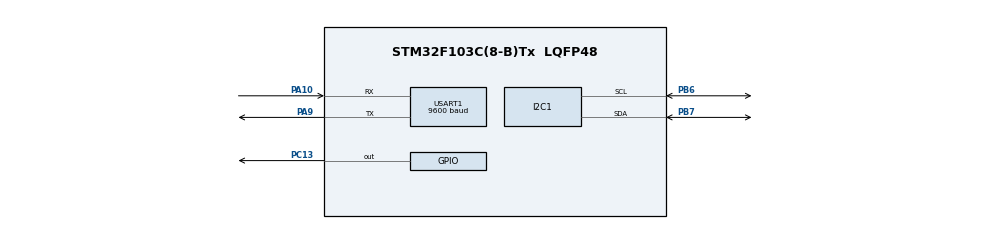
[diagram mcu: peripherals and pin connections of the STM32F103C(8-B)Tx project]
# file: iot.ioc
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Mcu.Family=STM32F1
Mcu.Name=STM32F103C(8-B)Tx
Mcu.Package=LQFP48
NVIC.PriorityGroup=NVIC_PRIORITYGROUP_4
NVIC.USART1_IRQn=true\:0\:0\:false\:false\:true\:true\:true\:true
PA10.Mode=Asynchronous
PA10.Signal=USART1_RX
PA9.Mode=Asynchronous
PA9.Signal=USART1_TX
PB6.Mode=I2C
PB6.Signal=I2C1_SCL
PB7.Mode=I2C
PB7.Signal=I2C1_SDA
PC13-TAMPER-RTC.Signal=GPIO_Output
ProjectManager.HeapSize=0x200
ProjectManager.StackSize=0x400
ProjectManager.TargetToolchain=MDK-ARM V5.32
RCC.APB1Freq_Value=8000000
RCC.APB2Freq_Value=8000000
USART1.BaudRate=9600
USART1.VirtualMode=VM_ASYNC
VP_SYS_VS_ND.Mode=No_Debug
board=custom

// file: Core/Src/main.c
/* USER CODE BEGIN Header */
/**
  ******************************************************************************
  * @file           : main.c
  * @brief          : Main program body
  ******************************************************************************
  * @attention
  *
  * Copyright (c) 2023 STMicroelectronics.
  * All rights reserved.
  *
  * This software is licensed under terms that can be found in the LICENSE file
  * in the root directory of this software component.
  * If no LICENSE file comes with this software, it is provided AS-IS.
  *
  ******************************************************************************
  */
/* USER CODE END Header */
#include "main.h"
#include <string.h>
#define WIDTH 128
#define HEIGHT 64
#define WIRE_MAX 32
#define size_x 8
#define size_y 10
#define TW_START 0x08 // start
#define  TW_REP_START  0x10    // repeat start
#define  TW_MT_SLA_ACK 0x18   // truyen slave addr de ghi co ack
#define  TW_MT_SLA_NACK 0x20 //  truyen slave addr de ghi  ko co ack
#define  TW_MR_SLA_ACK 0x40   // truyen slave addr de doc co ack
#define  TW_MT_DATA_ACK 0x28 // gui dl co ack
#define  TW_MT_DATA_NACK 0x30  // nhan dl khong co ack
#define SSD1306_COLUMNADDR          0x21 ///< See datasheet
#define SSD1306_PAGEADDR            0x22        ///< See datasheet
#define BUFF_SIZE WIDTH*HEIGHT/8

#define addr_oled 0x78
#define MESS_SIZE 32

I2C_HandleTypeDef hi2c1;

UART_HandleTypeDef huart1;

void SystemClock_Config(void);
static void MX_GPIO_Init(void);
static void MX_I2C1_Init(void);
static void MX_USART1_UART_Init(void);

unsigned char buffer[BUFF_SIZE]; //
unsigned char buff[3];
unsigned char buff1[WIRE_MAX];
// rong 128 dai 64
const uint8_t Fonts_10x7 [] = {
0x00, 0x00, 0x00, 0x00, 0x00, 0x00, 0x00, 0x00, 0x00, 0x00,  // sp
0x10, 0x10, 0x10, 0x10, 0x10, 0x10, 0x00, 0x10, 0x00, 0x00,  // !
0x28, 0x28, 0x28, 0x00, 0x00, 0x00, 0x00, 0x00, 0x00, 0x00,  // "
0x24, 0x24, 0x7C, 0x24, 0x48, 0x7C, 0x48, 0x48, 0x00, 0x00,  // #
0x38, 0x54, 0x50, 0x38, 0x14, 0x54, 0x54, 0x38, 0x10, 0x00,  // $
0x20, 0x54, 0x58, 0x30, 0x28, 0x54, 0x14, 0x08, 0x00, 0x00,  // %
0x10, 0x28, 0x28, 0x10, 0x34, 0x48, 0x48, 0x34, 0x00, 0x00,  // &
0x10, 0x10, 0x10, 0x00, 0x00, 0x00, 0x00, 0x00, 0x00, 0x00,  // '
0x08, 0x10, 0x20, 0x20, 0x20, 0x20, 0x20, 0x20, 0x10, 0x08,  // (
0x20, 0x10, 0x08, 0x08, 0x08, 0x08, 0x08, 0x08, 0x10, 0x20,  // )
0x10, 0x38, 0x10, 0x28, 0x00, 0x00, 0x00, 0x00, 0x00, 0x00,  // *
0x00, 0x00, 0x10, 0x10, 0x7C, 0x10, 0x10, 0x00, 0x00, 0x00,  // +
0x00, 0x00, 0x00, 0x00, 0x00, 0x00, 0x00, 0x10, 0x10, 0x10,  // ,
0x00, 0x00, 0x00, 0x00, 0x00, 0x38, 0x00, 0x00, 0x00, 0x00,  // -
0x00, 0x00, 0x00, 0x00, 0x00, 0x00, 0x00, 0x10, 0x00, 0x00,  // .
0x08, 0x08, 0x10, 0x10, 0x10, 0x10, 0x20, 0x20, 0x00, 0x00,  // /
0x38, 0x44, 0x44, 0x54, 0x44, 0x44, 0x44, 0x38, 0x00, 0x00,  // 0
0x10, 0x30, 0x50, 0x10, 0x10, 0x10, 0x10, 0x10, 0x00, 0x00,  // 1
0x38, 0x44, 0x44, 0x04, 0x08, 0x10, 0x20, 0x7C, 0x00, 0x00,  // 2
0x38, 0x44, 0x04, 0x18, 0x04, 0x04, 0x44, 0x38, 0x00, 0x00,  // 3
0x08, 0x18, 0x28, 0x28, 0x48, 0x7C, 0x08, 0x08, 0x00, 0x00,  // 4
0x7C, 0x40, 0x40, 0x78, 0x04, 0x04, 0x44, 0x38, 0x00, 0x00,  // 5
0x38, 0x44, 0x40, 0x78, 0x44, 0x44, 0x44, 0x38, 0x00, 0x00,  // 6
0x7C, 0x04, 0x08, 0x10, 0x10, 0x20, 0x20, 0x20, 0x00, 0x00,  // 7
0x38, 0x44, 0x44, 0x38, 0x44, 0x44, 0x44, 0x38, 0x00, 0x00,  // 8
0x38, 0x44, 0x44, 0x44, 0x3C, 0x04, 0x44, 0x38, 0x00, 0x00,  // 9
0x00, 0x00, 0x10, 0x00, 0x00, 0x00, 0x00, 0x10, 0x00, 0x00,  // :
0x00, 0x00, 0x00, 0x10, 0x00, 0x00, 0x00, 0x10, 0x10, 0x10,  // ;
0x00, 0x00, 0x0C, 0x30, 0x40, 0x30, 0x0C, 0x00, 0x00, 0x00,  // <
0x00, 0x00, 0x00, 0x7C, 0x00, 0x7C, 0x00, 0x00, 0x00, 0x00,  // =
0x00, 0x00, 0x60, 0x18, 0x04, 0x18, 0x60, 0x00, 0x00, 0x00,  // >
0x38, 0x44, 0x04, 0x08, 0x10, 0x10, 0x00, 0x10, 0x00, 0x00,  // ?
0x38, 0x44, 0x4C, 0x54, 0x5C, 0x40, 0x40, 0x38, 0x00, 0x00,  // @
0x10, 0x28, 0x28, 0x28, 0x28, 0x7C, 0x44, 0x44, 0x00, 0x00,  // A
0x78, 0x44, 0x44, 0x78, 0x44, 0x44, 0x44, 0x78, 0x00, 0x00,  // B
0x38, 0x44, 0x40, 0x40, 0x40, 0x40, 0x44, 0x38, 0x00, 0x00,  // C
0x70, 0x48, 0x44, 0x44, 0x44, 0x44, 0x48, 0x70, 0x00, 0x00,  // D
0x7C, 0x40, 0x40, 0x7C, 0x40, 0x40, 0x40, 0x7C, 0x00, 0x00,  // E
0x7C, 0x40, 0x40, 0x78, 0x40, 0x40, 0x40, 0x40, 0x00, 0x00,  // F
0x38, 0x44, 0x40, 0x40, 0x5C, 0x44, 0x44, 0x38, 0x00, 0x00,  // G
0x44, 0x44, 0x44, 0x7C, 0x44, 0x44, 0x44, 0x44, 0x00, 0x00,  // H
0x38, 0x10, 0x10, 0x10, 0x10, 0x10, 0x10, 0x38, 0x00, 0x00,  // I
0x04, 0x04, 0x04, 0x04, 0x04, 0x04, 0x44, 0x38, 0x00, 0x00,  // J
0x44, 0x48, 0x50, 0x60, 0x50, 0x48, 0x48, 0x44, 0x00, 0x00,  // K
0x40, 0x40, 0x40, 0x40, 0x40, 0x40, 0x40, 0x7C, 0x00, 0x00,  // L
0x44, 0x6C, 0x6C, 0x54, 0x44, 0x44, 0x44, 0x44, 0x00, 0x00,  // M
0x44, 0x64, 0x64, 0x54, 0x54, 0x4C, 0x4C, 0x44, 0x00, 0x00,  // N
0x38, 0x44, 0x44, 0x44, 0x44, 0x44, 0x44, 0x38, 0x00, 0x00,  // O
0x78, 0x44, 0x44, 0x44, 0x78, 0x40, 0x40, 0x40, 0x00, 0x00,  // P
0x38, 0x44, 0x44, 0x44, 0x44, 0x44, 0x54, 0x38, 0x04, 0x00,  // Q
0x78, 0x44, 0x44, 0x44, 0x78, 0x48, 0x48, 0x44, 0x00, 0x00,  // R
0x38, 0x44, 0x40, 0x30, 0x08, 0x04, 0x44, 0x38, 0x00, 0x00,  // S
0x7C, 0x10, 0x10, 0x10, 0x10, 0x10, 0x10, 0x10, 0x00, 0x00,  // T
0x44, 0x44, 0x44, 0x44, 0x44, 0x44, 0x44, 0x38, 0x00, 0x00,  // U
0x44, 0x44, 0x44, 0x28, 0x28, 0x28, 0x10, 0x10, 0x00, 0x00,  // V
0x44, 0x44, 0x54, 0x54, 0x54, 0x6C, 0x28, 0x28, 0x00, 0x00,  // W
0x44, 0x28, 0x28, 0x10, 0x10, 0x28, 0x28, 0x44, 0x00, 0x00,  // X
0x44, 0x44, 0x28, 0x28, 0x10, 0x10, 0x10, 0x10, 0x00, 0x00,  // Y
0x7C, 0x04, 0x08, 0x10, 0x10, 0x20, 0x40, 0x7C, 0x00, 0x00,  // Z
0x18, 0x10, 0x10, 0x10, 0x10, 0x10, 0x10, 0x10, 0x10, 0x18,  // [
0x20, 0x20, 0x10, 0x10, 0x10, 0x10, 0x08, 0x08, 0x00, 0x00,  /* \ */
0x30, 0x10, 0x10, 0x10, 0x10, 0x10, 0x10, 0x10, 0x10, 0x30,  // ]
0x10, 0x28, 0x28, 0x44, 0x00, 0x00, 0x00, 0x00, 0x00, 0x00,  // ^
0x00, 0x00, 0x00, 0x00, 0x00, 0x00, 0x00, 0x00, 0x00, 0xFE,  // _
0x20, 0x10, 0x00, 0x00, 0x00, 0x00, 0x00, 0x00, 0x00, 0x00,  // `
0x00, 0x00, 0x38, 0x44, 0x3C, 0x44, 0x4C, 0x34, 0x00, 0x00,  // a
0x40, 0x40, 0x58, 0x64, 0x44, 0x44, 0x64, 0x58, 0x00, 0x00,  // b
0x00, 0x00, 0x38, 0x44, 0x40, 0x40, 0x44, 0x38, 0x00, 0x00,  // c
0x04, 0x04, 0x34, 0x4C, 0x44, 0x44, 0x4C, 0x34, 0x00, 0x00,  // d
0x00, 0x00, 0x38, 0x44, 0x7C, 0x40, 0x44, 0x38, 0x00, 0x00,  // e
0x0C, 0x10, 0x7C, 0x10, 0x10, 0x10, 0x10, 0x10, 0x00, 0x00,  // f
0x00, 0x00, 0x34, 0x4C, 0x44, 0x44, 0x4C, 0x34, 0x04, 0x78,  // g
0x40, 0x40, 0x58, 0x64, 0x44, 0x44, 0x44, 0x44, 0x00, 0x00,  // h
0x10, 0x00, 0x70, 0x10, 0x10, 0x10, 0x10, 0x10, 0x00, 0x00,  // i
0x10, 0x00, 0x70, 0x10, 0x10, 0x10, 0x10, 0x10, 0x10, 0xE0,  // j
0x40, 0x40, 0x48, 0x50, 0x60, 0x50, 0x48, 0x44, 0x00, 0x00,  // k
0x70, 0x10, 0x10, 0x10, 0x10, 0x10, 0x10, 0x10, 0x00, 0x00,  // l
0x00, 0x00, 0x78, 0x54, 0x54, 0x54, 0x54, 0x54, 0x00, 0x00,  // m
0x00, 0x00, 0x58, 0x64, 0x44, 0x44, 0x44, 0x44, 0x00, 0x00,  // n
0x00, 0x00, 0x38, 0x44, 0x44, 0x44, 0x44, 0x38, 0x00, 0x00,  // o
0x00, 0x00, 0x58, 0x64, 0x44, 0x44, 0x64, 0x58, 0x40, 0x40,  // p
0x00, 0x00, 0x34, 0x4C, 0x44, 0x44, 0x4C, 0x34, 0x04, 0x04,  // q
0x00, 0x00, 0x58, 0x64, 0x40, 0x40, 0x40, 0x40, 0x00, 0x00,  // r
0x00, 0x00, 0x38, 0x44, 0x30, 0x08, 0x44, 0x38, 0x00, 0x00,  // s
0x20, 0x20, 0x78, 0x20, 0x20, 0x20, 0x20, 0x18, 0x00, 0x00,  // t
0x00, 0x00, 0x44, 0x44, 0x44, 0x44, 0x4C, 0x34, 0x00, 0x00,  // u
0x00, 0x00, 0x44, 0x44, 0x28, 0x28, 0x28, 0x10, 0x00, 0x00,  // v
0x00, 0x00, 0x54, 0x54, 0x54, 0x6C, 0x28, 0x28, 0x00, 0x00,  // w
0x00, 0x00, 0x44, 0x28, 0x10, 0x10, 0x28, 0x44, 0x00, 0x00,  // x
0x00, 0x00, 0x44, 0x44, 0x28, 0x28, 0x10, 0x10, 0x10, 0x60,  // y
0x00, 0x00, 0x7C, 0x08, 0x10, 0x20, 0x40, 0x7C, 0x00, 0x00,  // z
0x18, 0x10, 0x10, 0x10, 0x20, 0x20, 0x10, 0x10, 0x10, 0x18,  // {
0x10, 0x10, 0x10, 0x10, 0x10, 0x10, 0x10, 0x10, 0x10, 0x10,  // |
0x30, 0x10, 0x10, 0x10, 0x08, 0x08, 0x10, 0x10, 0x10, 0x30,  // }
0x00, 0x00, 0x00, 0x74, 0x4C, 0x00, 0x00, 0x00, 0x00, 0x00,  // ~
};

uint8_t logo_bmp[] =
{ 0x00,0x00,0x00,0x00,0x00,0x00,
  0x00,0x00,0x1f,0xff,0xff,0xf0,
  0x00,0x00,0x3f,0xff,0xff,0xf0,
  0x00,0x00,0x3f,0xff,0xff,0xf0,
  0x00,0x00,0x3f,0xff,0xff,0xf0,
  0x00,0x00,0x3e,0x6f,0xe4,0xf0,
  0x00,0x00,0x3e,0xa7,0x20,0xf0,
  0x00,0x40,0x3e,0x0b,0x21,0xf0,
  0x01,0xf0,0x3e,0x83,0x20,0xf0,
  0x00,0xe0,0x3e,0x53,0x64,0xf0,
  0x00,0xe0,0x3f,0xff,0xff,0xf0,
  0x00,0x00,0x3f,0xff,0xff,0xf0,
  0x00,0x00,0x3f,0xff,0xff,0xf0,
  0x00,0x00,0x3f,0xff,0xef,0xf0,
  0x00,0x00,0x3f,0xfc,0xff,0xf0,
  0x00,0x00,0x3f,0xff,0x5f,0xf0,
  0x00,0x00,0x3f,0xef,0xbf,0xf0,
  0x00,0x00,0x3f,0xff,0xbf,0xf0,
  0x00,0x00,0x3f,0x73,0xef,0xf0,
  0x00,0x00,0x3d,0xdb,0xff,0xf0,
  0x00,0x00,0x3b,0x7e,0xff,0xf0,
  0x00,0x00,0x0d,0xfd,0xff,0xf0,
  0x00,0x00,0x1b,0xef,0xff,0xf0,
  0x00,0x00,0x6f,0xfb,0xff,0xf0,
  0x00,0x00,0xbf,0xdf,0xff,0xf0,
  0x00,0x00,0x3f,0xff,0xff,0xf0,
  0x00,0x00,0x3f,0xaf,0xff,0xf0,
  0x00,0x00,0x3f,0xff,0xff,0xf0,
  0x00,0x00,0x3f,0x5f,0xff,0xf0,
  0x00,0x00,0x3f,0xbf,0xff,0xf0,
  0x00,0x00,0x3e,0xff,0xff,0xf0,
  0x00,0x00,0xef,0xef,0xff,0xf0,
  0x00,0x00,0xfc,0xff,0xff,0xf0,
  0x00,0x01,0x3f,0xff,0xff,0xf0,
  0x00,0x14,0x39,0xff,0xff,0xf0,
  0x00,0x18,0x3b,0xff,0xff,0xf0,
  0x00,0x30,0x37,0xff,0xff,0xf0,
  0x00,0x10,0x37,0xff,0xff,0xf0,
  0x00,0x00,0x2f,0xff,0xff,0xf0,
  0x00,0x00,0x0f,0xff,0xff,0xf0,
  0x00,0x00,0x1f,0xff,0xff,0xf0,
  0x00,0x00,0x3f,0xff,0xff,0xf0,
  0x00,0x10,0x3f,0xff,0xff,0xf0,
  0x00,0x30,0x3f,0xff,0xff,0xf0,
  0x00,0x38,0x3f,0xff,0xff,0xf0,
  0x00,0x18,0x3f,0xff,0xff,0xf0,
  0x00,0x00,0x3f,0xff,0xff,0xf0,
  0x00,0x01,0x3f,0xff,0xff,0xf0,
  0x00,0x00,0xef,0xff,0xff,0xf0,
  0x00,0x00,0xef,0xff,0xff,0xf0,
  0x00,0x00,0x3f,0xff,0xff,0xf0,
  0x00,0x00,0x3f,0xff,0xff,0xf0,
  0x00,0x00,0x3f,0xff,0xff,0xf0,
  0x00,0x00,0x1f,0xff,0xff,0xf0,
  0x3f,0xff,0xdf,0xff,0xff,0xf0,
  0x3f,0xdf,0xff,0xff,0xff,0xf0,
  0x3f,0xdf,0xff,0xff,0xff,0xf0,
  0x30,0x88,0x13,0x02,0x04,0x70,
  0x30,0x88,0x13,0x02,0x04,0x70,
  0x30,0x89,0x03,0x10,0x04,0x70,
  0x30,0x89,0x83,0x10,0x04,0x70,
  0x30,0x00,0x13,0x02,0x00,0x30,
  0x30,0x20,0x13,0x02,0x01,0x30,
  0x3b,0xac,0xb7,0xea,0xcf,0x70,
  0x3f,0xff,0xff,0xff,0xff,0xf0,
  0x3f,0xff,0xff,0xff,0xff,0xf0,
  0x00,0x00,0x00,0x00,0x00,0x00,

};

void initBuff(){
     memset(buffer,0,BUFF_SIZE);
	 memset(buff,0,3);
	 memset(buff1,0,WIRE_MAX);
}

void write_cmd1(uint8_t c ){
	memset(buff,0,3);
	  buff[0]= 0x00;
	  buff[1] = c;
    HAL_I2C_Master_Transmit(&hi2c1,addr_oled,buff,2,100 );
}

void cmd_list(unsigned char*c, int n){

      unsigned char  bytesOut = 1;
     	memset(buff1,0,WIRE_MAX);

       while(n--) {
        if(bytesOut >= WIRE_MAX) {
					HAL_I2C_Master_Transmit(&hi2c1,addr_oled,buff1,WIRE_MAX,1000 );
         	memset(buff1,0,WIRE_MAX);
          bytesOut = 1;
        }
      buff1[bytesOut] = *c++;
      bytesOut++;
    }
     if(bytesOut>0){
			 HAL_I2C_Master_Transmit(&hi2c1,addr_oled,buff1,bytesOut,1000 );
		 }
}

void initDisplay()
{
    write_cmd1(0xAE);          // 0xAE // display off
    write_cmd1(0xD5);          // 0xD5 // set display clock division
    write_cmd1(0x80);          // the suggested ratio 0x80
    write_cmd1(0xA8);          // 0xA8 set multiplex
    write_cmd1(63);            // set height
    write_cmd1(0xD3);          // set display offset
    write_cmd1(0x00);           // no offset
    write_cmd1(0x40);            // line #0 setstartline
    write_cmd1(0x8D);          // 0x8D // chargepump
    write_cmd1(0x14);          //?? 0x10
    write_cmd1(0x20);          // memory mode
    write_cmd1(0x00);          // 0x0 act like ks0108
    write_cmd1(0xA1);           // segremap
    write_cmd1(0xC8);          // comscandec
    write_cmd1(0xDA);          // 0xDA set com pins
    write_cmd1(0x12);
    write_cmd1(0x81);          // 0x81 // set contract
    write_cmd1(0xCF);          //??  0x9F
    write_cmd1(0xD9);          // 0xd9 set pre-charge
    write_cmd1(0xF1);         //0x22
    write_cmd1(0xDB);          // SSD1306_SETVCOMDETECT
    write_cmd1(0x40);
    write_cmd1(0xA4);          // 0xA4 // display all on resume
    write_cmd1(0xA6);          // 0xA6 // normal display
    write_cmd1(0x2E);          // deactivate scroll
    write_cmd1(0xAF);          // --turn on oled panel
}

void display()
{

	  int  count = WIDTH * (HEIGHT / 8);
    uint8_t *ptr   = buffer;
    unsigned char bytesOut = 1;
	  unsigned char dlist1[] = {
     SSD1306_PAGEADDR,
     0,                         // Page start address
     0xFF,                      // Page end (not really, but works here)
     SSD1306_COLUMNADDR,
     0 };
	// Column start address
	  cmd_list(dlist1, sizeof(dlist1));
	  write_cmd1(WIDTH - 1);
		memset(buff1,0,WIRE_MAX);
		buff1[0] = 0x40;
		while(count--) {
      if(bytesOut >= WIRE_MAX) {
				HAL_I2C_Master_Transmit(&hi2c1,addr_oled,buff1,WIRE_MAX,1000 );
				memset(buff1,0,WIRE_MAX);
				 buff1[0] = 0x40;
        bytesOut = 1;
      }
			 buff1[bytesOut] =*ptr++ ;
       bytesOut++;
    }
		 if(bytesOut>0){
			 	HAL_I2C_Master_Transmit(&hi2c1,addr_oled,buff1,bytesOut,1000 );
		 }
}

void clear(){
   memset(buffer,0,BUFF_SIZE);
    display();
}

void drawpixel(int x, int y ){// draw hang y cot x

  if((x >= 0) && (x <WIDTH) && (y >= 0) && (y < HEIGHT)) {
    buffer[x + (y/8)*WIDTH] |=  (1 << (y&7)); //
   }
}

void drawBitmap(int x, int y, unsigned char bitmap[], int w, int  h) {

   int i, j;
   int byteWidth= (w+7)/8;
   int  byte = 0;
  for ( j = 0; j < h; j++) {
    for ( i = 0; i < w; i++) {

          if (i & 7)// 8 bit 1
          byte <<= 1;
          else
          byte = bitmap[j * byteWidth + i / 8];
         if(byte & 0x80){
            drawpixel(x + i,y+j);
         }
    }
  }
}

void drawImage(unsigned char bitmap[],int  LOGO_HEIGHT,int  LOGO_WIDTH){

    drawBitmap(
    (WIDTH  - LOGO_WIDTH ) / 2,
    (HEIGHT - LOGO_HEIGHT) / 2,
    bitmap, LOGO_WIDTH, LOGO_HEIGHT);
}

void drawChar(int16_t x, int16_t y, unsigned char c) {

    if ((x >= WIDTH) || x<0||             // Clip right
        (y >= HEIGHT) ||     y<0||        // Clip bottom
        ((x +  size_x - WIDTH- 1) > 0) ||   // Clip left
        ((y +  size_y - HEIGHT- 1) > 0)  ||  // Clip top
		     c<32   || c>126)            // not character
      return;
    int16_t t  = (c-32)*10;
    for (int8_t i = 0; i < 10; i++) {
      int8_t cha = Fonts_10x7[i+t];
      for (int8_t j = 0; j < 8; j++) {
        if(cha&0x80){
					drawpixel(x+j,y+i);
				}
				cha<<=1;
        //  0x1000
    }
   }
}

void drawChars(uint8_t *x, uint8_t *y,char mess){
     //   char c ;
//        if (*x<0||  (*x >= WIDTH))  {*x =0; clear(); }
//        if( *y>=HEIGHT) {*y =0; clear(); }
        if(*x +  size_x >= WIDTH){
           if((*y +  size_y >= HEIGHT)){
              *x=0;
             *y=0;
             clear();
           }
           else{
              *y+= size_y;
              *x =0;
           }
        }
         drawChar( *x,  *y,   mess);
        *x+=size_x;
}

unsigned char rxData[MESS_SIZE];
uint8_t tx;
uint8_t rx;
uint8_t in=0;
uint8_t curx;
uint8_t cury;
volatile uint8_t cnt =0;
volatile uint8_t clr =0;
volatile  uint8_t flag = 0;
void HAL_UART_RxCpltCallback(UART_HandleTypeDef *huart)
{
  /* Prevent unused argument(s) compilation warning */
  UNUSED(huart);
  /* NOTE: This function should not be modified, when the callback is needed,
           the HAL_UART_RxCpltCallback could be implemented in the user file
   */
	if(huart->Instance == huart1.Instance){
	    rxData[cnt++] = tx;
if(tx =='*')clr =1;
   // HAL_UART_Transmit(&huart1, &tx, 1,200);
    if(cnt>=MESS_SIZE){
      cnt =0;
    }
//		   cnt&=0x07;
      HAL_UART_Receive_IT(&huart1,&tx,1);
		flag = 1;
	}
}

void clean(){
  clear();
  memset(rxData,0,MESS_SIZE);
  curx = cury =0;
  cnt =0;
  in =0;
}

int main(void)
{

  /* MCU Configuration--------------------------------------------------------*/

  /* Reset of all peripherals, Initializes the Flash interface and the Systick. */
  HAL_Init();

  /* Configure the system clock */
  SystemClock_Config();

  /* Initialize all configured peripherals */
  MX_GPIO_Init();
  MX_I2C1_Init();
  MX_USART1_UART_Init();
  /* USER CODE BEGIN 2 */
  HAL_UART_Receive_IT(&huart1,&tx,1);
  /* USER CODE END 2 */
  initBuff();
  initDisplay();
  clear();
  /* Infinite loop */
  while (1)
  {
if(flag ==1){
 if(clr){ clean();
 clr =0;
 }
  HAL_GPIO_TogglePin(GPIOC, GPIO_PIN_13);
	//drawChar(5,5,rx);
  while(in!=cnt){
  drawChars(&curx,&cury,rxData[in]);

  in++;
  if(in>=MESS_SIZE) in =0;
    display();
  }
  flag =0;
}
  }
}

void SystemClock_Config(void)
{
  RCC_OscInitTypeDef RCC_OscInitStruct = {0};
  RCC_ClkInitTypeDef RCC_ClkInitStruct = {0};

  /** Initializes the RCC Oscillators according to the specified parameters
  * in the RCC_OscInitTypeDef structure.
  */
  RCC_OscInitStruct.OscillatorType = RCC_OSCILLATORTYPE_HSI;
  RCC_OscInitStruct.HSIState = RCC_HSI_ON;
  RCC_OscInitStruct.HSICalibrationValue = RCC_HSICALIBRATION_DEFAULT;
  RCC_OscInitStruct.PLL.PLLState = RCC_PLL_NONE;
  if (HAL_RCC_OscConfig(&RCC_OscInitStruct) != HAL_OK)
  {
    Error_Handler();
  }

  /** Initializes the CPU, AHB and APB buses clocks
  */
  RCC_ClkInitStruct.ClockType = RCC_CLOCKTYPE_HCLK|RCC_CLOCKTYPE_SYSCLK
                              |RCC_CLOCKTYPE_PCLK1|RCC_CLOCKTYPE_PCLK2;
  RCC_ClkInitStruct.SYSCLKSource = RCC_SYSCLKSOURCE_HSI;
  RCC_ClkInitStruct.AHBCLKDivider = RCC_SYSCLK_DIV1;
  RCC_ClkInitStruct.APB1CLKDivider = RCC_HCLK_DIV1;
  RCC_ClkInitStruct.APB2CLKDivider = RCC_HCLK_DIV1;

  if (HAL_RCC_ClockConfig(&RCC_ClkInitStruct, FLASH_LATENCY_0) != HAL_OK)
  {
    Error_Handler();
  }
}

static void MX_I2C1_Init(void)
{

  hi2c1.Instance = I2C1;
  hi2c1.Init.ClockSpeed = 100000;
  hi2c1.Init.DutyCycle = I2C_DUTYCYCLE_2;
  hi2c1.Init.OwnAddress1 = 0;
  hi2c1.Init.AddressingMode = I2C_ADDRESSINGMODE_7BIT;
  hi2c1.Init.DualAddressMode = I2C_DUALADDRESS_DISABLE;
  hi2c1.Init.OwnAddress2 = 0;
  hi2c1.Init.GeneralCallMode = I2C_GENERALCALL_DISABLE;
  hi2c1.Init.NoStretchMode = I2C_NOSTRETCH_DISABLE;
  if (HAL_I2C_Init(&hi2c1) != HAL_OK)
  {
    Error_Handler();
  }

}

static void MX_USART1_UART_Init(void)
{

  huart1.Instance = USART1;
  huart1.Init.BaudRate = 9600;
  huart1.Init.WordLength = UART_WORDLENGTH_8B;
  huart1.Init.StopBits = UART_STOPBITS_1;
  huart1.Init.Parity = UART_PARITY_NONE;
  huart1.Init.Mode = UART_MODE_TX_RX;
  huart1.Init.HwFlowCtl = UART_HWCONTROL_NONE;
  huart1.Init.OverSampling = UART_OVERSAMPLING_16;
  if (HAL_UART_Init(&huart1) != HAL_OK)
  {
    Error_Handler();
  }

}

static void MX_GPIO_Init(void)
{
  GPIO_InitTypeDef GPIO_InitStruct = {0};

  /* GPIO Ports Clock Enable */
  __HAL_RCC_GPIOC_CLK_ENABLE();
  __HAL_RCC_GPIOA_CLK_ENABLE();
  __HAL_RCC_GPIOB_CLK_ENABLE();

  /*Configure GPIO pin Output Level */
  HAL_GPIO_WritePin(GPIOC, GPIO_PIN_13, GPIO_PIN_RESET);

  /*Configure GPIO pin : PC13 */
  GPIO_InitStruct.Pin = GPIO_PIN_13;
  GPIO_InitStruct.Mode = GPIO_MODE_OUTPUT_PP;
  GPIO_InitStruct.Pull = GPIO_NOPULL;
  GPIO_InitStruct.Speed = GPIO_SPEED_FREQ_LOW;
  HAL_GPIO_Init(GPIOC, &GPIO_InitStruct);

}

void Error_Handler(void)
{
  __disable_irq();
  while (1)
  {
  }
}
